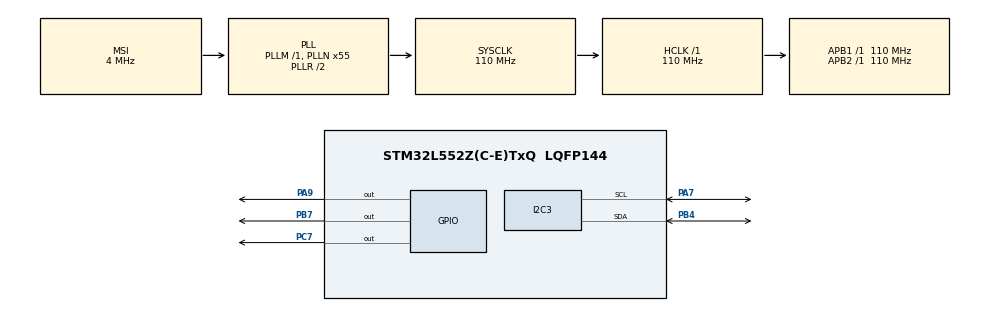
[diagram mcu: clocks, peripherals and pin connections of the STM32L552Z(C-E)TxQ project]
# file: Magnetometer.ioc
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I2C3.Timing=0x60514452
Mcu.Family=STM32L5
Mcu.Name=STM32L552Z(C-E)TxQ
Mcu.Package=LQFP144
Mcu.TrustZone=disable
NUCLEO-L552ZE-Q.BUTTON=1
NUCLEO-L552ZE-Q.LD1=true
NUCLEO-L552ZE-Q.LD2=true
NUCLEO-L552ZE-Q.LD3=true
NUCLEO-L552ZE-Q.VCP=true
NVIC.EXTI13_IRQn=true\:0\:0\:false\:false\:true\:false\:true\:true
NVIC.PriorityGroup=NVIC_PRIORITYGROUP_3
PA13\ (JTMS/SWDIO).Signal=DEBUG_JTMS-SWDIO
PA14\ (JTCK/SWCLK).Signal=DEBUG_JTCK-SWCLK
PA7.Mode=I2C
PA7.Signal=I2C3_SCL
PA9.Signal=GPIO_Output
PB3\ (JTDO/TRACESWO).Signal=DEBUG_JTDO-SWO
PB4\ (NJTRST).Mode=I2C
PB4\ (NJTRST).Signal=I2C3_SDA
PB7.Signal=GPIO_Output
PC13.Signal=PWR_WKUP2
PC14-OSC32_IN\ (PC14).Signal=RCC_OSC32_IN
PC15-OSC32_OUT\ (PC15).Signal=RCC_OSC32_OUT
PC7.Signal=GPIO_Output
PG7.Signal=LPUART1_TX
PG8.Signal=LPUART1_RX
ProjectManager.HeapSize=0x200
ProjectManager.StackSize=0x400
ProjectManager.TargetToolchain=STM32CubeIDE
RCC.ADCCLockSelection=RCC_ADCCLKSOURCE_SYSCLK
RCC.ADCFreq_Value=110000000
RCC.AHBFreq_Value=110000000
RCC.APB1Freq_Value=110000000
RCC.APB1TimFreq_Value=110000000
RCC.APB2Freq_Value=110000000
RCC.APB2TimFreq_Value=110000000
RCC.CK48CLockSelection=RCC_USBCLKSOURCE_HSI48
RCC.CortexFreq_Value=110000000
RCC.HCLKFreq_Value=110000000
RCC.HSE_VALUE=8000000
RCC.HSI48_VALUE=48000000
RCC.HSI_VALUE=16000000
RCC.LSE_VALUE=32768
RCC.MSI_VALUE=4000000
RCC.PLLN=55
RCC.PLLSAI1N=24
RCC.RTCClockSelection=RCC_RTCCLKSOURCE_LSE
RCC.SYSCLKFreq_VALUE=110000000
RCC.SYSCLKSource=RCC_SYSCLKSOURCE_PLLCLK
RCC.USBFreq_Value=48000000
RCC.VCOOutputFreq_Value=220000000
VP_ICACHE_VS_ICACHE.Mode=DirectMappedCache
VP_NUCLEO-L552ZE-Q_VS_BSP_COMMON.Mode=COMMON
VP_PWR_VS_DBSignals.Mode=DisableDeadBatterySignals
VP_PWR_VS_SECSignals.Mode=Security/Privilege
board=NUCLEO-L552ZE-Q

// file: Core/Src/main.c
/* USER CODE BEGIN Header */
/**
  ******************************************************************************
  * @file           : main.c
  * @brief          : Main program body
  ******************************************************************************
  * @attention
  *
  * Copyright (c) 2025 STMicroelectronics.
  * All rights reserved.
  *
  * This software is licensed under terms that can be found in the LICENSE file
  * in the root directory of this software component.
  * If no LICENSE file comes with this software, it is provided AS-IS.
  *
  ******************************************************************************
  */
/* USER CODE END Header */
#include "main.h"
#include "i2c.h"
#include "gpio.h"

/* USER CODE BEGIN Includes */
#include "../../Drivers/MLX90393_Driver/mlx90393_i2c.hpp"

/* USER CODE END Includes */

COM_InitTypeDef BspCOMInit;
I2C_HandleTypeDef hi2c3;

void SystemClock_Config(void);
static void MX_GPIO_Init(void);
static void MX_ICACHE_Init(void);
static void MX_I2C3_Init(void);

/* USER CODE BEGIN 0 */
MLX90393 mlx90393(&hi2c3);

/* USER CODE END 0 */

int main(void)
{

  /* MCU Configuration--------------------------------------------------------*/

  /* Reset of all peripherals, Initializes the Flash interface and the Systick. */
  HAL_Init();

  /* Configure the system clock */
  SystemClock_Config();

  /* Initialize all configured peripherals */
  MX_GPIO_Init();
  MX_ICACHE_Init();
  MX_I2C3_Init();

  /* Initialize leds */
  BSP_LED_Init(LED_GREEN);
  BSP_LED_Init(LED_BLUE);
  BSP_LED_Init(LED_RED);

  /* Initialize USER push-button, will be used to trigger an interrupt each time it's pressed.*/
  BSP_PB_Init(BUTTON_USER, BUTTON_MODE_EXTI);

  /* Initialize COM1 port (115200, 8 bits (7-bit data + 1 stop bit), no parity */
  BspCOMInit.BaudRate   = 115200;
  BspCOMInit.WordLength = COM_WORDLENGTH_8B;
  BspCOMInit.StopBits   = COM_STOPBITS_1;
  BspCOMInit.Parity     = COM_PARITY_NONE;
  BspCOMInit.HwFlowCtl  = COM_HWCONTROL_NONE;
  if (BSP_COM_Init(COM1, &BspCOMInit) != BSP_ERROR_NONE)
  {
    Error_Handler();
  }

  /* Infinite loop */
  while (1)
  {

  }
}

void SystemClock_Config(void)
{
  RCC_OscInitTypeDef RCC_OscInitStruct = {0};
  RCC_ClkInitTypeDef RCC_ClkInitStruct = {0};

  /** Configure the main internal regulator output voltage
  */
  if (HAL_PWREx_ControlVoltageScaling(PWR_REGULATOR_VOLTAGE_SCALE0) != HAL_OK)
  {
    Error_Handler();
  }

  /** Initializes the RCC Oscillators according to the specified parameters
  * in the RCC_OscInitTypeDef structure.
  */
  RCC_OscInitStruct.OscillatorType = RCC_OSCILLATORTYPE_MSI;
  RCC_OscInitStruct.MSIState = RCC_MSI_ON;
  RCC_OscInitStruct.MSICalibrationValue = RCC_MSICALIBRATION_DEFAULT;
  RCC_OscInitStruct.MSIClockRange = RCC_MSIRANGE_6;
  RCC_OscInitStruct.PLL.PLLState = RCC_PLL_ON;
  RCC_OscInitStruct.PLL.PLLSource = RCC_PLLSOURCE_MSI;
  RCC_OscInitStruct.PLL.PLLM = 1;
  RCC_OscInitStruct.PLL.PLLN = 55;
  RCC_OscInitStruct.PLL.PLLP = RCC_PLLP_DIV7;
  RCC_OscInitStruct.PLL.PLLQ = RCC_PLLQ_DIV2;
  RCC_OscInitStruct.PLL.PLLR = RCC_PLLR_DIV2;
  if (HAL_RCC_OscConfig(&RCC_OscInitStruct) != HAL_OK)
  {
    Error_Handler();
  }

  /** Initializes the CPU, AHB and APB buses clocks
  */
  RCC_ClkInitStruct.ClockType = RCC_CLOCKTYPE_HCLK|RCC_CLOCKTYPE_SYSCLK
                              |RCC_CLOCKTYPE_PCLK1|RCC_CLOCKTYPE_PCLK2;
  RCC_ClkInitStruct.SYSCLKSource = RCC_SYSCLKSOURCE_PLLCLK;
  RCC_ClkInitStruct.AHBCLKDivider = RCC_SYSCLK_DIV1;
  RCC_ClkInitStruct.APB1CLKDivider = RCC_HCLK_DIV1;
  RCC_ClkInitStruct.APB2CLKDivider = RCC_HCLK_DIV1;

  if (HAL_RCC_ClockConfig(&RCC_ClkInitStruct, FLASH_LATENCY_5) != HAL_OK)
  {
    Error_Handler();
  }
}

static void MX_I2C3_Init(void)
{

  hi2c3.Instance = I2C3;
  hi2c3.Init.Timing = 0x60514452;
  hi2c3.Init.OwnAddress1 = 0;
  hi2c3.Init.AddressingMode = I2C_ADDRESSINGMODE_7BIT;
  hi2c3.Init.DualAddressMode = I2C_DUALADDRESS_DISABLE;
  hi2c3.Init.OwnAddress2 = 0;
  hi2c3.Init.OwnAddress2Masks = I2C_OA2_NOMASK;
  hi2c3.Init.GeneralCallMode = I2C_GENERALCALL_DISABLE;
  hi2c3.Init.NoStretchMode = I2C_NOSTRETCH_DISABLE;
  if (HAL_I2C_Init(&hi2c3) != HAL_OK)
  {
    Error_Handler();
  }

  /** Configure Analogue filter
  */
  if (HAL_I2CEx_ConfigAnalogFilter(&hi2c3, I2C_ANALOGFILTER_ENABLE) != HAL_OK)
  {
    Error_Handler();
  }

  /** Configure Digital filter
  */
  if (HAL_I2CEx_ConfigDigitalFilter(&hi2c3, 0) != HAL_OK)
  {
    Error_Handler();
  }

}

static void MX_ICACHE_Init(void)
{

  /** Enable instruction cache in 1-way (direct mapped cache)
  */
  if (HAL_ICACHE_ConfigAssociativityMode(ICACHE_1WAY) != HAL_OK)
  {
    Error_Handler();
  }
  if (HAL_ICACHE_Enable() != HAL_OK)
  {
    Error_Handler();
  }

}

static void MX_GPIO_Init(void)
{

  /* GPIO Ports Clock Enable */
  __HAL_RCC_GPIOC_CLK_ENABLE();
  __HAL_RCC_GPIOA_CLK_ENABLE();
  __HAL_RCC_GPIOB_CLK_ENABLE();

}

void Error_Handler(void)
{
  __disable_irq();
  while (1)
  {
  }
}
